# PIC32CZ4010CA80100 register map
Vendor: Microchip Technology; Series: PIC32CZCA80; File version: 0
CPU: CM7 r1p1, little endian, MPU, FPU, double-precision FPU, I-cache, D-cache, ITCM, DTCM, 3 interrupt priority bits, 222 interrupts
Registers are 32-bit, read-write, reset 0x0 unless marked. A register's access mark holds for its fields unless they carry their own. Offsets are from the block's base; [hi:lo] are bit positions; {n}, {i} and the like mark numbered series; 'fields as' and 'values as' point back to an identical list.

## CoreDebug
Base 0xE000ED00
0x30 DFSR — Debug Fault Status Register
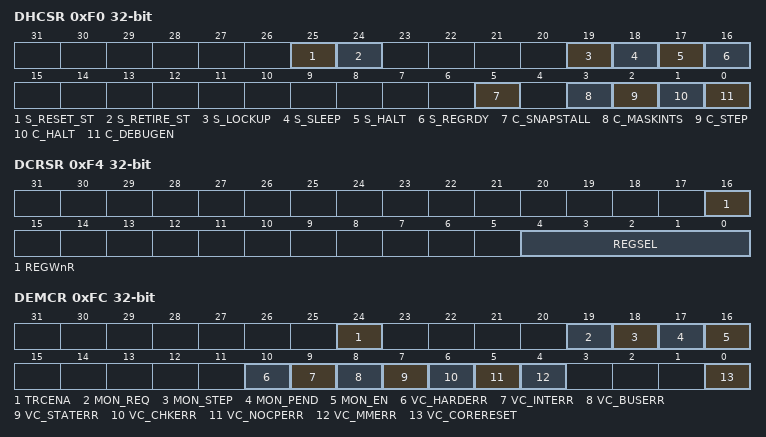
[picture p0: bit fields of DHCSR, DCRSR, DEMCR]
0xF0 DHCSR — Debug Halting Control and Status Register
  [25] S_RESET_ST, [24] S_RETIRE_ST, [19] S_LOCKUP, [18] S_SLEEP, [17] S_HALT, [16] S_REGRDY, [5] C_SNAPSTALL, [3] C_MASKINTS, [2] C_STEP, [1] C_HALT, [0] C_DEBUGEN
0xF4 DCRSR wo — Debug Core Register Selector Register
  [16] REGWnR, [4:0] REGSEL
0xF8 DCRDR — Debug Core Register Data Register
0xFC DEMCR — Debug Exception and Monitor Control Register
  [24] TRCENA, [19] MON_REQ, [18] MON_STEP, [17] MON_PEND, [16] MON_EN, [10] VC_HARDERR, [9] VC_INTERR, [8] VC_BUSERR, [7] VC_STATERR, [6] VC_CHKERR, [5] VC_NOCPERR, [4] VC_MMERR, [0] VC_CORERESET

## DWT — Data Watchpoint and Trace Register
Base 0xE0001000
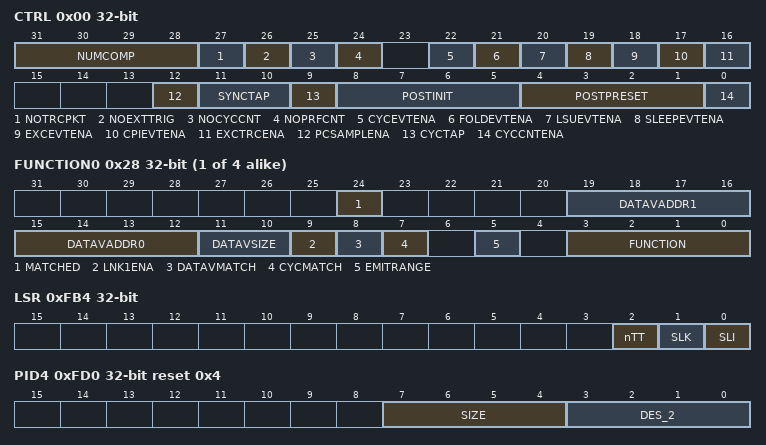
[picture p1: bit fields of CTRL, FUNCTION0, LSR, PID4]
0x00 CTRL — Control Register
  [31:28] NUMCOMP, [27] NOTRCPKT, [26] NOEXTTRIG, [25] NOCYCCNT, [24] NOPRFCNT, [22] CYCEVTENA, [21] FOLDEVTENA, [20] LSUEVTENA, [19] SLEEPEVTENA, [18] EXCEVTENA, [17] CPIEVTENA, [16] EXCTRCENA, [12] PCSAMPLENA, [11:10] SYNCTAP, [9] CYCTAP, [8:5] POSTINIT, [4:1] POSTPRESET, [0] CYCCNTENA
0x04 CYCCNT — Cycle Count Register
0x08 CPICNT — CPI Count Register
  [7:0] CPICNT
0x0C EXCCNT — Exception Overhead Count Register
  [7:0] EXCCNT
0x10 SLEEPCNT — Sleep Count Register
  [7:0] SLEEPCNT
0x14 LSUCNT — LSU Count Register
  [7:0] LSUCNT
0x18 FOLDCNT — Folded-instruction Count Register
  [7:0] FOLDCNT
0x1C PCSR ro — Program Counter Sample Register
{0x20+0x10*i} COMP{i} (i=0..3) — Comparator Register {i}
{0x24+0x10*i} MASK{i} (i=0..3) — Mask Register {i}
  [4:0] MASK
{0x28+0x10*i} FUNCTION{i} (i=0..3) — Function Register {i}
  [24] MATCHED, [19:16] DATAVADDR1, [15:12] DATAVADDR0, [11:10] DATAVSIZE, [9] LNK1ENA, [8] DATAVMATCH, [7] CYCMATCH, [5] EMITRANGE, [3:0] FUNCTION
0xFB0 LAR wo — DWT Software Lock Access Register
  [31:0] KEY — Lock access control
    0xC5ACCE55=UNLOCK (Unlock key value)
0xFB4 LSR ro — DWT Software Lock Status Register
  [2] nTT — Not thirty-two bit
  [1] SLK — Software Lock status
  [0] SLI — Software Lock implemented
0xFD0 PID4 ro reset 0x4 — DWT Peripheral Identification Register 4
  [7:4] SIZE — 4KB count
  [3:0] DES_2 — JEP106 continuation code
{0xFC0+4i} PID{i} ro (i=5..7) — DWT Peripheral Identification Register {i}
0xFE0 PID0 ro reset 0x2 — DWT Peripheral Identification Register 0
  [7:0] PART_0 — Part number bits[7:0]
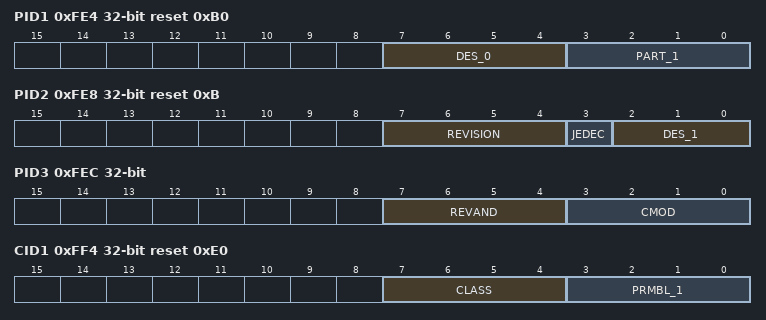
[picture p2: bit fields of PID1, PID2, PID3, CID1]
0xFE4 PID1 ro reset 0xB0 — DWT Peripheral Identification Register 1
  [7:4] DES_0 — JEP106 identification code bits [3:0]
  [3:0] PART_1 — Part number bits[11:8]
0xFE8 PID2 ro reset 0xB — DWT Peripheral Identification Register 2
  [7:4] REVISION — Component revision
  [3] JEDEC — JEDEC assignee value is used
  [2:0] DES_1 — JEP106 identification code bits[6:4]
0xFEC PID3 ro — DWT Peripheral Identification Register 3
  [7:4] REVAND
  [3:0] CMOD — Customer Modified
0xFF0 CID0 ro reset 0xD — DWT Component Identification Register 0
  [7:0] PRMBL_0 — CoreSight component identification preamble
0xFF4 CID1 ro reset 0xE0 — DWT Component Identification Register 1
  [7:4] CLASS — CoreSight component class
  [3:0] PRMBL_1 — CoreSight component identification preamble
0xFF8 CID2 ro reset 0x5 — DWT Component Identification Register 2
  [7:0] PRMBL_2 — CoreSight component identification preamble
0xFFC CID3 ro reset 0xB1 — DWT Component Identification Register 3
  [7:0] PRMBL_3 — CoreSight component identification preamble

## EIC — External Interrupt Controller
Base 0x44800000
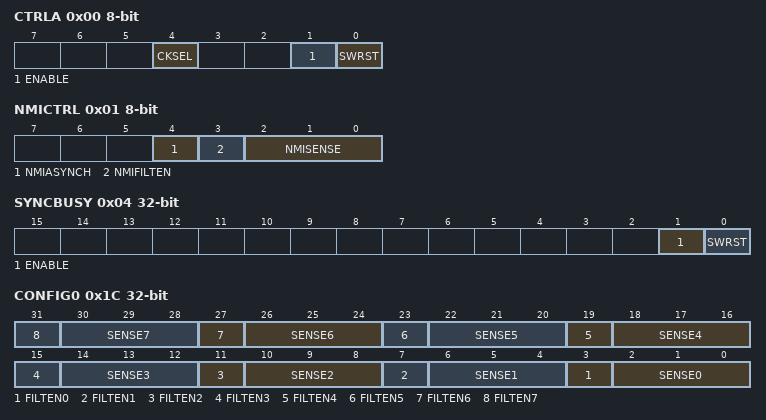
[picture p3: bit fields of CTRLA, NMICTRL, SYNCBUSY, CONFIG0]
0x00 CTRLA 8-bit — Control A
  [4] CKSEL — Clock Selection
    0=CLK_GCLK (Clocked by GCLK); 1=CLK_ULP32K (Clocked by ULP32K)
  [1] ENABLE
  [0] SWRST — Software Reset
0x01 NMICTRL 8-bit — Non-Maskable Interrupt Control
  [4] NMIASYNCH — Asynchronous Edge Detection Mode
    0=SYNC (Edge detection is clock synchronously operated); 1=ASYNC (Edge detection is clock asynchronously operated)
  [3] NMIFILTEN — Non-Maskable Interrupt Filter Enable
  [2:0] NMISENSE — Non-Maskable Interrupt Sense Configuration
    0=NONE (No detection); 1=RISE (Rising-edge detection); 2=FALL (Falling-edge detection); 3=BOTH (Both-edges detection); 4=HIGH (High-level detection); 5=LOW (Low-level detection)
0x02 NMIFLAG 16-bit write-1-clears — Non-Maskable Interrupt Flag Status and Clear
  [0] NMI — Non-Maskable Interrupt
0x04 SYNCBUSY ro — Synchronization Busy
  [1] ENABLE — Enable Synchronization Busy Status
  [0] SWRST — Software Reset Synchronization Busy Status
0x08 EVCTRL — Event Control
  [15:0] EXTINTEO — External Interrupt Event Output Enable
0x0C INTENCLR write-1-clears — Interrupt Enable Clear
  [15:0] EXTINT — External Interrupt Enable
0x10 INTENSET write-1-sets — Interrupt Enable Set
  [15:0] EXTINT — External Interrupt Enable
0x14 INTFLAG write-1-clears — Interrupt Flag Status and Clear
  [15:0] EXTINT — External Interrupt
0x18 ASYNCH — External Interrupt Asynchronous Mode
  [15:0] ASYNCH — Asynchronous Edge Detection Mode
    values as NMICTRL.NMIASYNCH
0x1C CONFIG0 — External Interrupt Sense Configuration
  [4n+3] FILTEN{n} (n=0..7) — Filter Enable {n}
  [4n+2:4n] SENSE{n} (n=0..7) — Input Sense Configuration {n}
    0=NONE (No detection); 1=RISE (Rising edge detection); 2=FALL (Falling edge detection); 3=BOTH (Both edges detection); 4=HIGH (High level detection); 5=LOW (Low level detection)
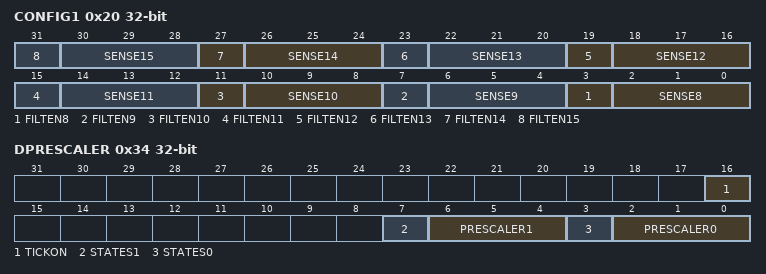
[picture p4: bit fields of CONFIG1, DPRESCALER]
0x20 CONFIG1 — External Interrupt Sense Configuration
  [4n-29] FILTEN{n} (n=8..15) — Filter Enable {n}
  [4n-30:4n-32] SENSE{n} (n=8..15) — Input Sense Configuration {n}
    values as CONFIG0.SENSE0
0x30 DEBOUNCEN — Debouncer Enable
  [15:0] DEBOUNCEN
0x34 DPRESCALER — Debouncer Prescaler
  [16] TICKON — Pin Sampler frequency selection
    0=CLK_GCLK_EIC (Clocked by GCLK); 1=CLK_LFREQ (Clocked by Low Frequency Clock)
  [7] STATES1 — Debouncer number of states
    0=LFREQ3 (3 low frequency samples); 1=LFREQ7 (7 low frequency samples)
  [6:4] PRESCALER1 — Debouncer Prescaler
    0=DIV2 (EIC clock divided by 2); 1=DIV4 (EIC clock divided by 4); 2=DIV8 (EIC clock divided by 8); 3=DIV16 (EIC clock divided by 16); 4=DIV32 (EIC clock divided by 32); 5=DIV64 (EIC clock divided by 64); 6=DIV128 (EIC clock divided by 128); 7=DIV256 (EIC clock divided by 256)
  [3] STATES0 — Debouncer number of states
    values as STATES1
  [2:0] PRESCALER0 — Debouncer Prescaler
    values as PRESCALER1
0x38 PINSTATE ro
  [15:0] PINSTATE

## Notices in the file
Copyright (c) 2026 Microchip Technology Inc.
SPDX-License-Identifier: Apache-2.0
Licensed under the Apache License, Version 2.0 (the "License");
you may not use this file except in compliance with the License.
You may obtain a copy of the License at
http://www.apache.org/licenses/LICENSE-2.0
Unless required by applicable law or agreed to in writing, software
distributed under the License is distributed on an "AS IS" BASIS,
WITHOUT WARRANTIES OR CONDITIONS OF ANY KIND, either express or implied.
See the License for the specific language governing permissions and
limitations under the License.
